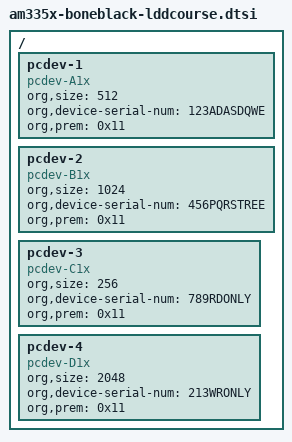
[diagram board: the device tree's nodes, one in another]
/ {
    pcdev-1 {
            compatible = "pcdev-A1x";
            org,size = <512>;
            org,device-serial-num = "123ADASDQWE";
            org,prem = <0x11>;
    };

    pcdev-2 {
            compatible = "pcdev-B1x";
            org,size = <1024>;
            org,device-serial-num = "456PQRSTREE";
            org,prem = <0x11>;
    };

    pcdev-3 {
            compatible = "pcdev-C1x";
            org,size = <256>;
            org,device-serial-num = "789RDONLY";
            org,prem = <0x11>;
    };

    pcdev-4 {
            compatible = "pcdev-D1x";
            org,size = <2048>;
            org,device-serial-num = "213WRONLY";
            org,prem = <0x11>;
    }; 
};
